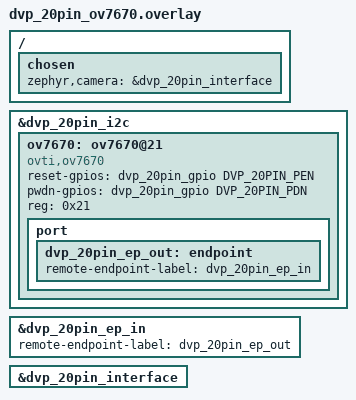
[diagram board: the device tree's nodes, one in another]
/*
 * Copyright 2024 NXP
 *
 * SPDX-License-Identifier: Apache-2.0
 */

/{
	chosen {
		zephyr,camera = &dvp_20pin_interface;
	};
};

&dvp_20pin_i2c {
	ov7670: ov7670@21 {
		compatible = "ovti,ov7670";
		reset-gpios = <&dvp_20pin_gpio DVP_20PIN_PEN GPIO_ACTIVE_HIGH>;
		pwdn-gpios  = <&dvp_20pin_gpio DVP_20PIN_PDN GPIO_ACTIVE_HIGH>;
		reg = <0x21>;

		port {
			dvp_20pin_ep_out: endpoint {
				remote-endpoint-label = "dvp_20pin_ep_in";
			};
		};
	};
};

&dvp_20pin_ep_in {
	remote-endpoint-label = "dvp_20pin_ep_out";
};

&dvp_20pin_interface {
	status = "okay";
};
